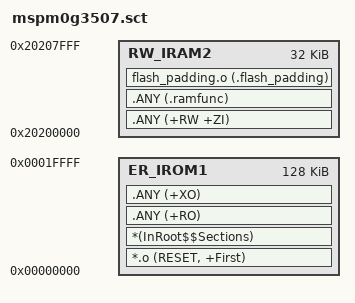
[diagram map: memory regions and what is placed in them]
; *************************************************************
; *** Scatter-Loading Description File generated by uVision ***
; *************************************************************

LR_IROM1 0x00000000 NOCOMPRESS 0x00020000  {    ; load region size_region
  ER_IROM1 0x00000000 ALIGNALL 8 0x00020000  {  ; load address = execution address
   *.o (RESET, +First)
   *(InRoot$$Sections)
   .ANY (+RO)
   .ANY (+XO)
  }
  RW_IRAM2 0x20200000 0x00008000  {  ; RW data
   .ANY (+RW +ZI)
   .ANY (.ramfunc)
   flash_padding.o (.flash_padding)
  }
}
